# GT32U2086 register map
Vendor: FPTTelecom
Registers are 32-bit, read-write, reset 0x0 unless marked. A register's access mark holds for its fields unless they carry their own. Offsets are from the block's base; [hi:lo] are bit positions.

## I2C0 — I2C0 - INTER INTEGRATED CIRCUIT I2C0 : 0x50080000 - 0x5008FFFF (64 KB) Separate TX/RX DMA controls and latched interrupt status.
Base 0x50080000
0x00 IER — RW I2C Enable Register bit[0] ENABLE
  [0] ENABLE — Enable the I2C controller
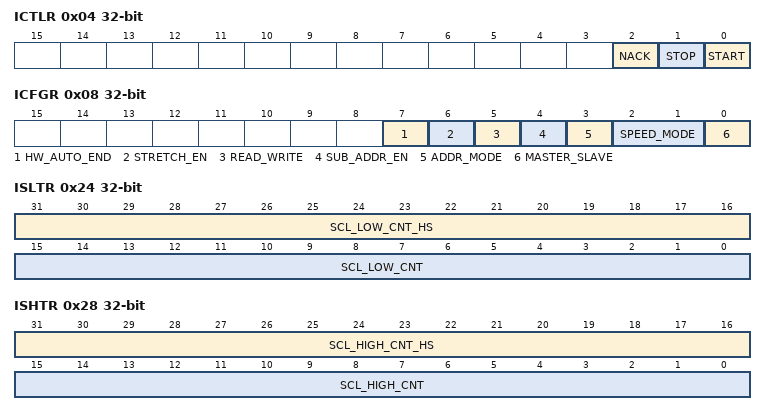
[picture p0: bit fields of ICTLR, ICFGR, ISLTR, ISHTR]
0x04 ICTLR — RW I2C Control Register bit[0] START | bit[1] STOP | bit[2] NACK
  [2] NACK — Request a NACK response in slave mode
  [1] STOP — Request STOP generation
  [0] START — Request START generation; hardware clears the bit after accepting the request
0x08 ICFGR — RW I2C Configuration Register bit[0] MASTER_SLAVE | bit[2:1] SPEED_MODE | bit[3] ADDR_MODE | bit[4] SUB_ADDR_EN | bit[5] READ_WRITE | bit[6] STRETCH_EN | bit[7] HW_AUTO_END
  [7] HW_AUTO_END — Master automatically generates STOP after the byte count completes
  [6] STRETCH_EN — Enable clock stretching in slave mode
  [5] READ_WRITE — Master transfer direction: 0=write, 1=read
  [4] SUB_ADDR_EN — Enable the 8-bit subaddress phase and repeated START when reading a register
  [3] ADDR_MODE — Address width: 0=7 bit, 1=10 bit
  [2:1] SPEED_MODE — Speed mode: SS/FS, FSP, HS or UFS
  [0] MASTER_SLAVE — Select role: 0=slave, 1=master
0x0C ITSAR — RW I2C Target Slave Address Register bit[9:0] SLAVE_ADDR
  [9:0] SLAVE_ADDR — 7- or 10-bit slave address, excluding the R/W bit
0x10 ISRAR — RW I2C Slave Register Address bit[7:0] SLAVE_REG_ADDR
  [7:0] SLAVE_REG_ADDR — 8-bit register address for a combined memory-read transaction
0x14 ITDR — RW I2C Transmit Data Register bit[7:0] TX_DATA
  [7:0] TX_DATA — Transmit data; writing the register pushes the TX FIFO
0x18 IRDR ro — RO I2C Receive Data Register bit[7:0] RX_DATA
  [7:0] RX_DATA — Receive data; reading the register pops the RX FIFO
0x1C IBCR — RW I2C Byte Count Register bit[7:0] BYTE_COUNT
  [7:0] BYTE_COUNT — Number of bytes transmitted/received in the transaction; hardware encoding range 0..255
0x20 ISPTR — RW I2C Spike Time Register bit[15:0] SPIKE_CNT
  [15:0] SPIKE_CNT — Number of i2c_clk cycles used for spike filtering
0x24 ISLTR — RW I2C SCL Low Time Register bit[15:0] SCL_LOW_CNT | bit[31:16] SCL_LOW_CNT_HS
  [31:16] SCL_LOW_CNT_HS — Number of SCL-low cycles during the master-code phase of HS mode
  [15:0] SCL_LOW_CNT — Number of SCL-low cycles for SS/FS/FSP/UFS
0x28 ISHTR — RW I2C SCL High Time Register bit[15:0] SCL_HIGH_CNT | bit[31:16] SCL_HIGH_CNT_HS
  [31:16] SCL_HIGH_CNT_HS — Programmed value for the master-code phase of HS mode
  [15:0] SCL_HIGH_CNT — Programmed SCL-high duration for SS/FS/FSP/UFS
0x2C ISSTR — RW I2C START Setup Time Register bit[15:0] START_SETUP_CNT
  [15:0] START_SETUP_CNT — Number of START setup cycles
0x30 ISTHTR — RW I2C START Hold Time Register bit[15:0] START_HOLD_CNT
  [15:0] START_HOLD_CNT — Number of START hold cycles
0x34 ISPSTR — RW I2C STOP Setup Time Register bit[15:0] STOP_SETUP_CNT
  [15:0] STOP_SETUP_CNT — Number of STOP setup cycles
0x38 ISDHTR — RW I2C SDA Hold Time Register bit[15:0] SDA_HOLD_CNT
  [15:0] SDA_HOLD_CNT — Number of SDA hold cycles
0x3C ITTR — RW I2C TBUF Time Register bit[15:0] TBUF_CNT
  [15:0] TBUF_CNT — Number of bus-free cycles
0x40 ISCSLTR — RW I2C SCL Stuck Low Time Register bit[15:0] SCL_STUCK_LOW_CNT
  [15:0] SCL_STUCK_LOW_CNT — Number of cycles before reporting SCL stuck-low
0x44 ISDSLTR — RW I2C SDA Stuck Low Time Register bit[15:0] SDA_STUCK_LOW_CNT
  [15:0] SDA_STUCK_LOW_CNT — Number of cycles before reporting SDA stuck-low
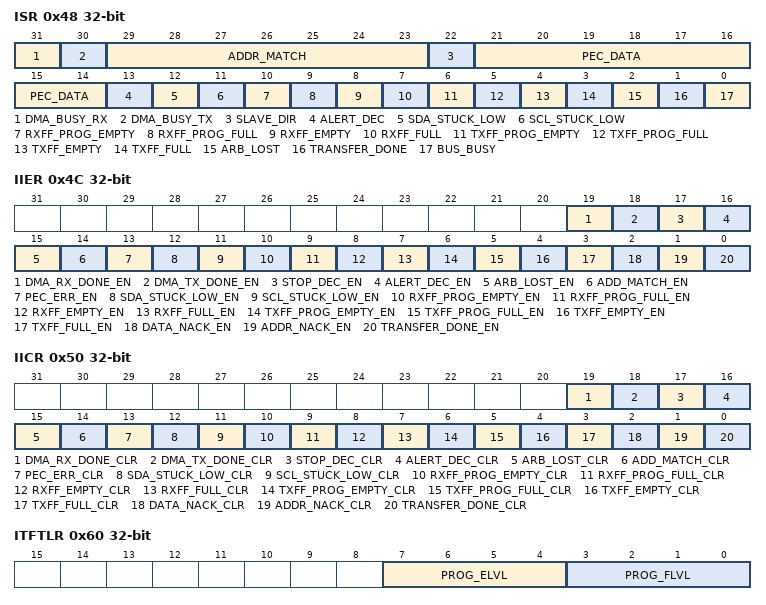
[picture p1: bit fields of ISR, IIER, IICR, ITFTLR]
0x48 ISR ro — RO I2C status; address/data NACK are reported in IITR
  [31] DMA_BUSY_RX — RX DMA busy
  [30] DMA_BUSY_TX — TX DMA busy
  [29:23] ADDR_MATCH — Matched slave address
  [22] SLAVE_DIR — Slave transfer direction
  [21:14] PEC_DATA — Current PEC value
  [13] ALERT_DEC — SMBus ALERT detected
  [12] SDA_STUCK_LOW — SDA held low detected
  [11] SCL_STUCK_LOW — SCL held low detected
  [10] RXFF_PROG_EMPTY — RX FIFO reached programmable-empty threshold
  [9] RXFF_PROG_FULL — RX FIFO reached programmable-full threshold
  [8] RXFF_EMPTY — RX FIFO empty
  [7] RXFF_FULL — RX FIFO full
  [6] TXFF_PROG_EMPTY — TX FIFO reached programmable-empty threshold
  [5] TXFF_PROG_FULL — TX FIFO reached programmable-full threshold
  [4] TXFF_EMPTY — TX FIFO empty
  [3] TXFF_FULL — TX FIFO full
  [2] ARB_LOST — Master lost arbitration
  [1] TRANSFER_DONE — All BYTE_COUNT bytes completed
  [0] BUS_BUSY — I2C bus busy
0x4C IIER — RW I2C Interrupt Enable Register bit[0] TRANSFER_DONE_EN | bit[1] ADDR_NACK_EN | bit[2] DATA_NACK_EN | bit[3] TXFF_FULL_EN | bit[4] TXFF_EMPTY_EN | bit[5] TXFF_PROG_FULL_EN | bit[6] TXFF_PROG_EMPTY_EN | bit[7] RXFF_FULL_EN | bit[8] RXFF_EMPTY_EN | bit[9] RXFF_PROG_FULL_EN | bit[10] RXFF_PROG_EMPTY_EN | bit[11] SCL_STUCK_LOW_EN | bit[12] SDA_STUCK_LOW_EN | bit[13] PEC_ERR_EN | bit[14] ADD_MATCH_EN | bit[15] ARB_LOST_EN | bit[16] ALERT_DEC_EN | bit[17] STOP_DEC_EN | bit[18] DMA_TX_DONE_EN | bit[19] DMA_RX_DONE_EN
  [19] DMA_RX_DONE_EN — Enable RX DMA-done interrupt
  [18] DMA_TX_DONE_EN — Enable TX DMA-done interrupt
  [17] STOP_DEC_EN — Enable the STOP-detection interrupt
  [16] ALERT_DEC_EN — Enable interrupt for SMBus ALERT
  [15] ARB_LOST_EN — Enable interrupt for arbitration-lost
  [14] ADD_MATCH_EN — Enable interrupt for address-match
  [13] PEC_ERR_EN — Enable the PEC-error interrupt
  [12] SDA_STUCK_LOW_EN — Enable interrupt for SDA stuck-low
  [11] SCL_STUCK_LOW_EN — Enable interrupt for SCL stuck-low
  [10] RXFF_PROG_EMPTY_EN — Enable interrupt for RX FIFO programmable-empty
  [9] RXFF_PROG_FULL_EN — Enable interrupt for RX FIFO programmable-full
  [8] RXFF_EMPTY_EN — Enable interrupt for RX FIFO empty
  [7] RXFF_FULL_EN — Enable interrupt for RX FIFO full
  [6] TXFF_PROG_EMPTY_EN — Enable interrupt for TX FIFO programmable-empty
  [5] TXFF_PROG_FULL_EN — Enable interrupt for TX FIFO programmable-full
  [4] TXFF_EMPTY_EN — Enable interrupt for TX FIFO empty
  [3] TXFF_FULL_EN — Enable interrupt for TX FIFO full
  [2] DATA_NACK_EN — Enable interrupt for data-NACK
  [1] ADDR_NACK_EN — Enable interrupt for address-NACK
  [0] TRANSFER_DONE_EN — Enable transfer-done interrupt; master hardware STOP is selected by ICFGR.HW_AUTO_END
0x50 IICR — RW I2C Interrupt Clear Register bit[0] TRANSFER_DONE_CLR | bit[1] ADDR_NACK_CLR | bit[2] DATA_NACK_CLR | bit[3] TXFF_FULL_CLR | bit[4] TXFF_EMPTY_CLR | bit[5] TXFF_PROG_FULL_CLR | bit[6] TXFF_PROG_EMPTY_CLR | bit[7] RXFF_FULL_CLR | bit[8] RXFF_EMPTY_CLR | bit[9] RXFF_PROG_FULL_CLR | bit[10] RXFF_PROG_EMPTY_CLR | bit[11] SCL_STUCK_LOW_CLR | bit[12] SDA_STUCK_LOW_CLR | bit[13] PEC_ERR_CLR | bit[14] ADD_MATCH_CLR | bit[15] ARB_LOST_CLR | bit[16] ALERT_DEC_CLR | bit[17] STOP_DEC_CLR | bit[18] DMA_TX_DONE_CLR | bit[19] DMA_RX_DONE_CLR
  [19] DMA_RX_DONE_CLR — Clear RX DMA-done interrupt
  [18] DMA_TX_DONE_CLR — Clear TX DMA-done interrupt
  [17] STOP_DEC_CLR — Clear the STOP-detection flag
  [16] ALERT_DEC_CLR — Clear the SMBus ALERT
  [15] ARB_LOST_CLR — Clear the arbitration-lost
  [14] ADD_MATCH_CLR — Clear the address-match
  [13] PEC_ERR_CLR — Clear the PEC-error flag
  [12] SDA_STUCK_LOW_CLR — Clear the SDA stuck-low
  [11] SCL_STUCK_LOW_CLR — Clear the SCL stuck-low
  [10] RXFF_PROG_EMPTY_CLR — Clear the RX FIFO programmable-empty
  [9] RXFF_PROG_FULL_CLR — Clear the RX FIFO programmable-full
  [8] RXFF_EMPTY_CLR — Clear the RX FIFO empty
  [7] RXFF_FULL_CLR — Clear the RX FIFO full
  [6] TXFF_PROG_EMPTY_CLR — Clear the TX FIFO programmable-empty
  [5] TXFF_PROG_FULL_CLR — Clear the TX FIFO programmable-full
  [4] TXFF_EMPTY_CLR — Clear the TX FIFO empty
  [3] TXFF_FULL_CLR — Clear the TX FIFO full
  [2] DATA_NACK_CLR — Clear the data-NACK
  [1] ADDR_NACK_CLR — Clear the address-NACK
  [0] TRANSFER_DONE_CLR — Clear the transfer-done
0x54 IBCER — RW I2C Bus Clear Enable Register bit[0] BUS_CLR
  [0] BUS_CLR — Enable the bus-clear procedure
0x58 IDIER — RW I2C Device ID Enable Register bit[0] DEV_ID
  [0] DEV_ID — Enable the Device ID read operation
0x5C ISRER — RW I2C Software Reset Enable Register bit[0] SW_RESET
  [0] SW_RESET — Enable software reset via general call
0x60 ITFTLR — RW I2C TX FIFO Threshold Level bit[3:0] PROG_FLVL | bit[7:4] PROG_ELVL
  [7:4] PROG_ELVL — Programmable-empty threshold of the TX FIFO
  [3:0] PROG_FLVL — Programmable-full threshold of the TX FIFO
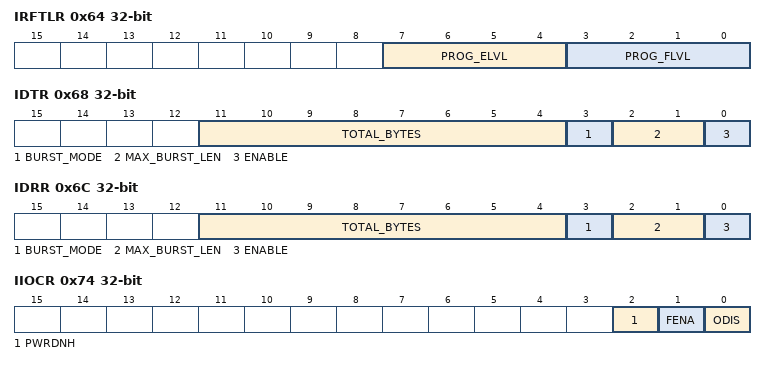
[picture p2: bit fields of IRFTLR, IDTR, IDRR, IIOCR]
0x64 IRFTLR — RW I2C RX FIFO Threshold Level bit[3:0] PROG_FLVL | bit[7:4] PROG_ELVL
  [7:4] PROG_ELVL — Programmable-empty threshold of the RX FIFO
  [3:0] PROG_FLVL — Programmable-full threshold of the RX FIFO
0x68 IDTR — I2C TX DMA request control
  [11:4] TOTAL_BYTES — Total TX DMA bytes
  [3] BURST_MODE — 0=SINGLE, 1=BURST
  [2:1] MAX_BURST_LEN — Singles per burst: 2/4/8/16
  [0] ENABLE — Enable TX DMA requests
0x6C IDRR — I2C RX DMA request control
  [11:4] TOTAL_BYTES — Total RX DMA bytes
  [3] BURST_MODE — 0=SINGLE, 1=BURST
  [2:1] MAX_BURST_LEN — Singles per burst: 2/4/8/16
  [0] ENABLE — Enable RX DMA requests
0x70 ISDIR — RW I2C Slave Device ID Register bit[23:0] DEV_ID
  [23:0] DEV_ID — 24-bit slave Device ID
0x74 IIOCR — RW I2C IO Configuration Register bit[0] ODIS | bit[1] FENA | bit[2] PWRDNH
  [2] PWRDNH — Control power-down of the I2C I/O cell
  [1] FENA — Force output enable of the I2C I/O cell
  [0] ODIS — Control output disable of the I2C I/O cell
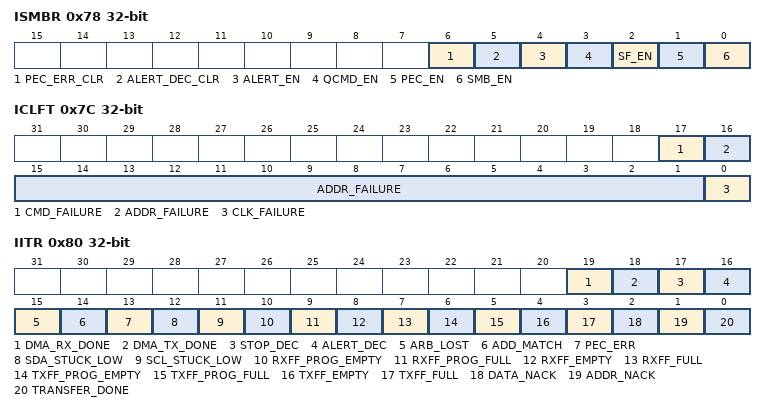
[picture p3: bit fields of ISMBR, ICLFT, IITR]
0x78 ISMBR — RW I2C SMBus Control Register bit[0] SMB_EN | bit[1] PEC_EN | bit[2] SF_EN | bit[3] QCMD_EN | bit[4] ALERT_EN | bit[5] ALERT_DEC_CLR | bit[6] PEC_ERR_CLR
  [6] PEC_ERR_CLR — Clear the PEC-error status
  [5] ALERT_DEC_CLR — Clear the ALERT-detect status
  [4] ALERT_EN — Enable SMBus ALERT
  [3] QCMD_EN — Enable SMBus quick-command
  [2] SF_EN — Enable the spike filter in SMBus mode
  [1] PEC_EN — Enable PEC generation/checking
  [0] SMB_EN — Enable SMBus
0x7C ICLFT ro — RO I2C Clock Failure Detect Register bit[0] CLK_FAILURE | bit[16:1] ADDR_FAILURE | bit[17] CMD_FAILURE
  [17] CMD_FAILURE — Command causing the failure: 0=write, 1=read
  [16:1] ADDR_FAILURE — Register address for the failed transaction
  [0] CLK_FAILURE — Clock failure detected
0x80 IITR ro — RO I2C Interrupt Status Register
  [19] DMA_RX_DONE — RX DMA-done interrupt active
  [18] DMA_TX_DONE — TX DMA-done interrupt active
  [17] STOP_DEC — STOP-detection interrupt active
  [16] ALERT_DEC — Interrupt SMBus ALERT active
  [15] ARB_LOST — Interrupt arbitration-lost active
  [14] ADD_MATCH — Interrupt address-match active
  [13] PEC_ERR — PEC-error interrupt active
  [12] SDA_STUCK_LOW — Interrupt SDA stuck-low active
  [11] SCL_STUCK_LOW — Interrupt SCL stuck-low active
  [10] RXFF_PROG_EMPTY — Interrupt RX FIFO programmable-empty active
  [9] RXFF_PROG_FULL — Interrupt RX FIFO programmable-full active
  [8] RXFF_EMPTY — Interrupt RX FIFO empty active
  [7] RXFF_FULL — Interrupt RX FIFO full active
  [6] TXFF_PROG_EMPTY — Interrupt TX FIFO programmable-empty active
  [5] TXFF_PROG_FULL — Interrupt TX FIFO programmable-full active
  [4] TXFF_EMPTY — Interrupt TX FIFO empty active
  [3] TXFF_FULL — Interrupt TX FIFO full active
  [2] DATA_NACK — Interrupt data-NACK active
  [1] ADDR_NACK — Interrupt address-NACK active
  [0] TRANSFER_DONE — Interrupt transfer-done active
